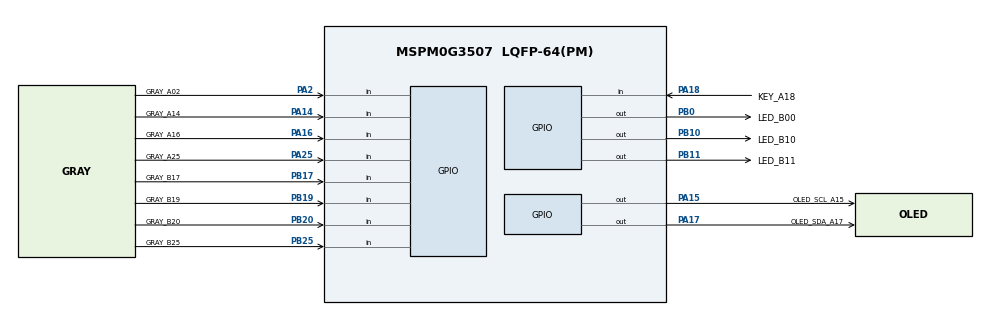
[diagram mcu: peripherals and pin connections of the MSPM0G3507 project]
/**
 * AI AGENTS: Do not edit this file directly. There is no validation or error feedback when
 * editing manually — mistakes will be silent until the file is loaded in SysConfig.
 * Use the SysConfig MCP server instead to make changes with immediate error reporting.
 *
 * These arguments were used when this file was generated. They will be automatically applied on subsequent loads
 * via the GUI or CLI. Run CLI with '--help' for additional information on how to override these arguments.
 * @cliArgs --device "MSPM0G350X" --part "Default" --package "LQFP-64(PM)" --product "mspm0_sdk@2.11.00.07"
 * @v2CliArgs --device "MSPM0G3507" --package "LQFP-64(PM)" --product "mspm0_sdk@2.11.00.07"
 * @versions {"tool":"1.28.0+4696"}
 */

/**
 * Import the modules used in this configuration.
 */
const GPIO   = scripting.addModule("/ti/driverlib/GPIO", {}, false);
const GPIO1  = GPIO.addInstance();
const GPIO2  = GPIO.addInstance();
const GPIO3  = GPIO.addInstance();
const GPIO4  = GPIO.addInstance();
const SYSCTL = scripting.addModule("/ti/driverlib/SYSCTL");

/**
 * Write custom configuration values to the imported modules.
 */
GPIO1.$name                         = "GPIO_LEDS";
GPIO1.associatedPins.create(3);
GPIO1.associatedPins[0].$name       = "LED_B00";
GPIO1.associatedPins[0].pin.$assign = "PB0";
GPIO1.associatedPins[1].$name       = "LED_B10";
GPIO1.associatedPins[1].pin.$assign = "PB10";
GPIO1.associatedPins[2].$name       = "LED_B11";
GPIO1.associatedPins[2].pin.$assign = "PB11";

const Board = scripting.addModule("/ti/driverlib/Board", {}, false);

GPIO2.$name                         = "GPIO_GRAY";
GPIO2.associatedPins.create(8);
GPIO2.associatedPins[0].$name       = "GRAY_A02";
GPIO2.associatedPins[0].direction   = "INPUT";
GPIO2.associatedPins[0].pin.$assign = "PA2";
GPIO2.associatedPins[1].$name       = "GRAY_B19";
GPIO2.associatedPins[1].direction   = "INPUT";
GPIO2.associatedPins[1].pin.$assign = "PB19";
GPIO2.associatedPins[2].$name       = "GRAY_B17";
GPIO2.associatedPins[2].direction   = "INPUT";
GPIO2.associatedPins[2].pin.$assign = "PB17";
GPIO2.associatedPins[3].$name       = "GRAY_A16";
GPIO2.associatedPins[3].direction   = "INPUT";
GPIO2.associatedPins[3].pin.$assign = "PA16";
GPIO2.associatedPins[4].$name       = "GRAY_A14";
GPIO2.associatedPins[4].direction   = "INPUT";
GPIO2.associatedPins[4].pin.$assign = "PA14";
GPIO2.associatedPins[5].$name       = "GRAY_B20";
GPIO2.associatedPins[5].direction   = "INPUT";
GPIO2.associatedPins[5].pin.$assign = "PB20";
GPIO2.associatedPins[6].$name       = "GRAY_B25";
GPIO2.associatedPins[6].direction   = "INPUT";
GPIO2.associatedPins[6].pin.$assign = "PB25";
GPIO2.associatedPins[7].$name       = "GRAY_A25";
GPIO2.associatedPins[7].direction   = "INPUT";
GPIO2.associatedPins[7].pin.$assign = "PA25";

GPIO3.$name                              = "GPIO_KEY";
GPIO3.associatedPins[0].$name            = "KEY_A18";
GPIO3.associatedPins[0].direction        = "INPUT";
GPIO3.associatedPins[0].internalResistor = "PULL_UP";
GPIO3.associatedPins[0].interruptEn      = true;
GPIO3.associatedPins[0].polarity         = "FALL";
GPIO3.associatedPins[0].pin.$assign      = "PA18";

GPIO4.$name                              = "GPIO_OLED";
GPIO4.associatedPins.create(2);
GPIO4.associatedPins[0].$name            = "OLED_SCL_A15";
GPIO4.associatedPins[0].direction        = "OUTPUT";
GPIO4.associatedPins[0].initialValue     = "SET";
GPIO4.associatedPins[0].internalResistor = "PULL_UP";
GPIO4.associatedPins[0].hiZ              = "ENABLE";
GPIO4.associatedPins[0].pin.$assign      = "PA15";
GPIO4.associatedPins[1].$name            = "OLED_SDA_A17";
GPIO4.associatedPins[1].direction        = "OUTPUT";
GPIO4.associatedPins[1].initialValue     = "SET";
GPIO4.associatedPins[1].internalResistor = "PULL_UP";
GPIO4.associatedPins[1].hiZ              = "ENABLE";
GPIO4.associatedPins[1].pin.$assign      = "PA17";

SYSCTL.SYSPLL_CLK2XEn        = true;
SYSCTL.SYSPLL_Pdiv           = 1;
SYSCTL.SYSPLL_Qdiv           = 5;
SYSCTL.SYSPLL_CLK2XDiv       = 3;
SYSCTL.MCLKSource            = "HSCLK";
SYSCTL.HSCLKSource           = "SYSPLLCLK2X";
SYSCTL.validateClkStatus     = true;
SYSCTL.forceDefaultClkConfig = false;

/**
 * Pinmux solution for unlocked pins/peripherals. This ensures that minor changes to the automatic solver in a future
 * version of the tool will not impact the pinmux you originally saw.  These lines can be completely deleted in order to
 * re-solve from scratch.
 */
Board.peripheral.$suggestSolution          = "DEBUGSS";
Board.peripheral.swclkPin.$suggestSolution = "PA20";
Board.peripheral.swdioPin.$suggestSolution = "PA19";
SYSCTL.peripheral.$suggestSolution         = "SYSCTL";
